# YTM32B1HA0 register map
Vendor: YTMicro; File version: 1.0
CPU: little endian, MPU, FPU, 2 interrupt priority bits
Registers are 32-bit, read-write, reset 0x0 unless marked. A register's access mark holds for its fields unless they carry their own. Offsets are from the block's base; [hi:lo] are bit positions; {n}, {i} and the like mark numbered series; 'fields as' and 'values as' point back to an identical list.

## SAI0
Base 0x401CC000; register names take the prefix SAI0_
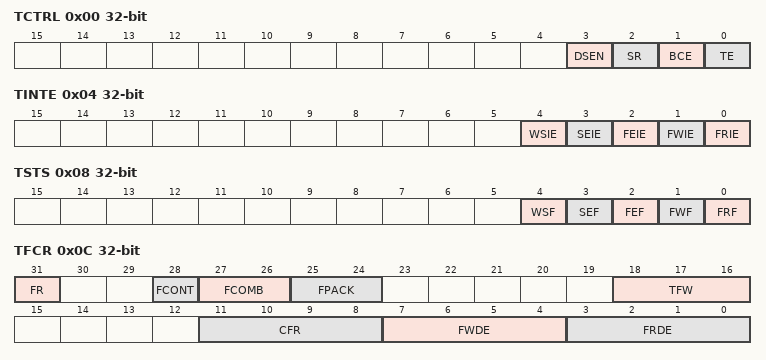
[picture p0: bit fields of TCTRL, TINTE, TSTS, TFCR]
0x00 TCTRL
  [3] DSEN — Configure the operation state of the transimitter in Deepsleep.
    0=Transmitter disable in Deepsleep; 1=Transmitter enable in Deepsleep
  [2] SR — When set, it will reset FIFO and the internal transmitter logic.
    0=No effect; 1=Software reset
  [1] BCE — Enables the transmit bit clock, separately from the TE.
    0=Transmit bit clock is disabled when TE is cleared; 1=Transmit bit clock is enabled
  [0] TE — Enable bit for the transmitter. After this bit is write 0, it remains set until the end of the current frame.
    0=Transmitter is disabled; 1=Transmitter is enabled
0x04 TINTE
  [all] fields
    0=Disable the interrupt; 1=Enable the interrupt
  [4] WSIE — Enable bit for word start interrupt.
  [3] SEIE — Enable bit for sync error interrupt.
  [2] FEIE — Enable bit for FIFO error interrupt.
  [1] FWIE — Enable bit for FIFO warning interrupt.
  [0] FRIE — Enable bit for FIFO request interrupt.
0x08 TSTS
  [4] WSF — Indicates the start of the word.
  [3] SEF — Indicates an error is detected on the frame sync which generated externally.
  [2] FEF — Indicates an FIFO underrun has been detected on enableb FIFOs.
  [1] FWF — Indicates at least one of the enabled FIFOs is empty.
  [0] FRF — Indicates at least one of the enabled FIFOs has words less or equal to the FIFO watermark.
0x0C TFCR
  [31] FR wo — FIFO software reset. Clears the data in the FIFO and sets the FIFO read pointer and write pointer to the same value. When the transmitter is disabled or the FIFO error occurs, this bit can be set.
  [28] FCONT — When configured, the SAI will continue transmitting when a FIFO error has been detected.
    0=After FIFO error occurs and the FIFO error flag is cleared, the SAI continues from the start of the next frame; 1=After FIFO error occurs and the FIFO error flag is cleared, the SAI continues from the same word that caused the FIFO error
  [27:26] FCOMB — When FIFO combine mode enabled on FIFO reads, the transmit data will alternate the read between the enabled FIFOs. The first word will be transmitted from the first enabled FIFO and the second word will be transmitted from the second FIFO. The first word of the frame is always transmitted from the first enabled FIFO. ewline When FIFO combine mode enabled on FIFO writes, soft writing to any FIFO data will alternate the write between the enabled FIFOs. The first write will store data in the first enabled FIFO and the second write will store data in the second enabled FIFO.
    0=FIFO combine mode disabled; 1=FIFO combine mode enabled on FIFO reads; 2=FIFO combine mode enabled on FIFO writes; 3=FIFO combine mode enabled on FIFO reads and FIFO writes
  [25:24] FPACK — Enalbes packing of 8-bit data or 16-bit data into 32-bit FIFO word. ewline The first word in each frame always start with a new 32-bit FIFO word.
    0=FIFO packing mode disabled; 1=8-bit FIFO packing mode enabled; 1=16-bit FIFO packing mode enabled
  [18:16] TFW — Configures the watermark level for the enabled FIFOs
  [11:8] CFR wo — Resets the FIFO pointers for the specific channel. It should only be set when a channel is disabled or the FIFO error flag is set.
  [7:4] FWDE — Enable the DMA request for the specific channel.
  [3:0] FRDE — Enable the DMA request for the specific channel.
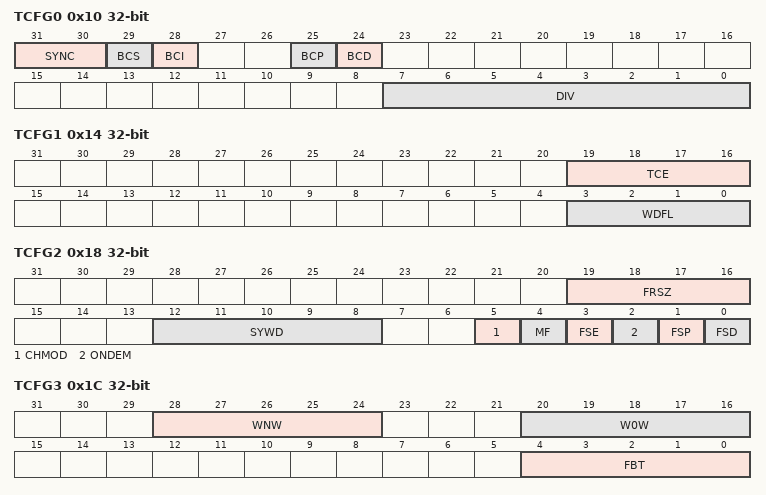
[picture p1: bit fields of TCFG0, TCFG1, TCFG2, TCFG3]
0x10 TCFG0
  [31:30] SYNC — Configures between asynchronous and synchronous modes of operation. In the synchronous mode, it operate with the synchronous bit clock and frame sync.
    0=Asynchronous mode; 1=Synchronous with the receiver(it should be in asynchronous mode); 2=Synchronous with another SAI transmitter(it should be in asynchronous mode); 3=Synchronous with another SAI receiver(it should be in asynchronous mode)
  [29] BCS — In asynchronous mode, swaps the bit clock with the receiver. This allows the transmitter and receiver to share the same bit clock, but the transmitter continues to use the transmit frame sync. ewline In synchronous mode, the transmitter and the receiver should be set to the same value. ewline When both set, the transmitter and the receiver both use the transmitter bit clock.
    0=Use the normal bit clock source; 1=Swap the bit clock source
  [28] BCI — When using an internally generated bit clock, enabling this bit will allow the transmitter to use the bit clock delayed by the pad. ewline When using an externally generated bit clock, it has no effect.
    0=No effect; 1=Use the bit clock delayed by the pad
  [25] BCP — Configures the polarity of the bit clock.
    0=Bit clock is active high with drive outputs on rising edge and sample inputs on falling edge; 1=Bit clock is active low with drive outputs on falling edge and sample inputs on rising edge
  [24] BCD — Configures the direction of the bit clock.
    0=Bit clock is generated externally in slave mode; 1=Bit clock is generated internally in master mode
  [7:0] DIV — Divide the audio master clock to generate teh bit clock. The division value is (DIV+1)*2
0x14 TCFG1
  [19:16] TCE — Enable the corresponding data channels for tranmit. Changing this field take effect immediately at the end of the frame.
  [3:0] WDFL
0x18 TCFG2
  [19:16] FRSZ — Configures the number of words in each frame. The number of words in the frame is (FRSZ+1).
  [12:8] SYWD — Configures the length of the frame sync in number of bit clock. The length is (SYWD+1) bit clock cycles.
  [5] CHMOD — Configures if the transmit data pins are TDM mode or ouput mode.
    0=TDM mode. The transmit data pins are tri-stated when slots are masked or channels are disabled.; 1=Output mode. The transmit data pins output zero when slots are masked or channels are disabled.
  [4] MF — Configures whether the LSB or the MSB is transmitted first.
    0=LSB first; 1=MSB first
  [3] FSE
    0=Frame sync asserts with the first bit of the frame; 1=Frame sync asserts one bit before the first bit of the frame
  [2] ONDEM — Configures that the frame sync is only generated when the FIFO warning flag is cleared and the frame sync is generated internally.
    0=Internal frame sync is generated continuously; 1=Internal frame sync is generated when the FIFO warning flag is clear
  [1] FSP — Configures the polarity of the frame sync.
    0=Frame sync is active high; 1=Frame sync is active low
  [0] FSD — Configures the direction of the frame sync.
    0=Frame sync is generated externally in slave mode; 1=Frame sync is generated internally in master mode
0x1C TCFG3
  [28:24] WNW — Configure the number of bits in each word except the first word in the frame. The number of bits in each word is (WNW+1) and should be no less than 8.
  [20:16] W0W — Configure the number of bits in the first word in each frame. The number of bits in the first word is (W0W+1) and should be no less than 8.
  [4:0] FBT — Configures the bit index for the first bit transmitted for each word.
{0x20+4i} TDATA{i} (i=0..3)
  [31:0] TDATA wo — Writes to this field will push the data into the FIFO when the FIFO is not full.
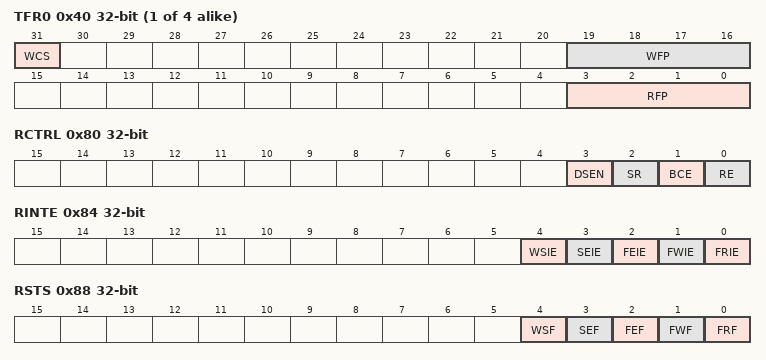
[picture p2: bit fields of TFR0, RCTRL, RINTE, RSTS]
{0x40+4i} TFR{i} (i=0..3)
  [31] WCS ro — Indicates FIFO of this channel is to be write next during FIFO combine mode.
  [19:16] WFP
  [3:0] RFP
0x60 TMR
  [15:0] TWM — Configure whether the transmit word is masked for the corresponding word in the frame.
0x80 RCTRL
  [3] DSEN — Configure the operation state of the receiver in Deepsleep.
    0=Receiver disable in Deepsleep; 1=Receiver enable in Deepsleep
  [2] SR — When set, it will reset FIFO and the internal receiver logic.
    0=No effect; 1=Software reset
  [1] BCE — Enables the receive bit clock, separately from the RE.
    0=Receive bit clock is disabled when RE is cleared; 1=Receive bit clock is enabled
  [0] RE — Enable bit for the receiver. After this bit is write 0, it remains set until the end of the current frame.
    0=Receiver is disabled; 1=Receiver is enabled
0x84 RINTE
  fields as TINTE
0x88 RSTS
  [4] WSF — Indicates the start of the word.
  [3] SEF — Indicates an error is detected on the frame sync which generated externally.
  [2] FEF — Indicates an FIFO overrun has been detected on enableb FIFOs.
  [1] FWF — Indicates at least one of the enabled FIFOs is full.
  [0] FRF — Indicates at least one of the enabled FIFOs has words greater or than the FIFO watermark.
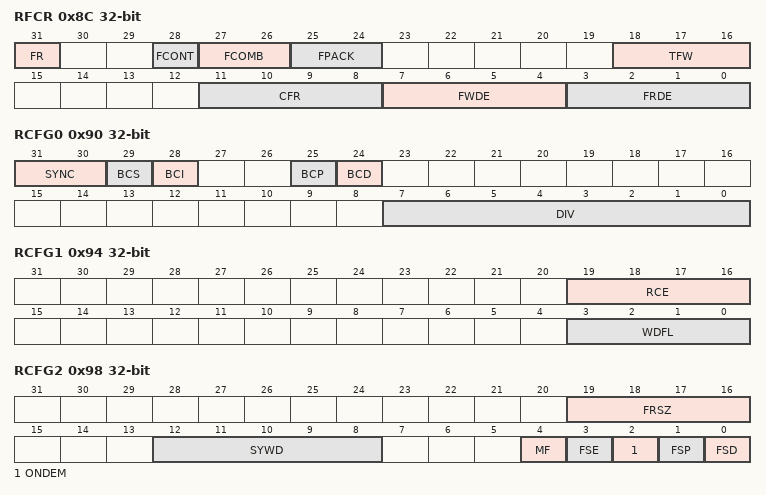
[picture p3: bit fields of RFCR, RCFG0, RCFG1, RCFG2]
0x8C RFCR
  [31] FR wo — FIFO software reset. Clears the data in the FIFO and sets the FIFO read pointer and write pointer to the same value. When the receiver is disabled or the FIFO error occurs, this bit can be set.
  [28] FCONT — When configured, the SAI will continue transmitting when a FIFO error has been detected.
    values as TFCR.FCONT
  [27:26] FCOMB — When FIFO combine mode enabled on FIFO write, the receive data will alternate the write between the enabled FIFOs. The first word will be stored to the first enabled FIFO and the second word will be stored to the second FIFO. The first word of the frame is always stored to the first enabled FIFO. ewline When FIFO combine mode enabled on FIFO reads, soft reading to any FIFO data will alternate the read between the enabled FIFOs. The first read will get data from the first enabled FIFO and the second read will get data from the second enabled FIFO.
    0=FIFO combine mode disabled; 1=FIFO combine mode enabled on FIFO writes; 2=FIFO combine mode enabled on FIFO reads; 3=FIFO combine mode enabled on FIFO reads and FIFO writes
  [25:24] FPACK — Enalbes packing of 8-bit data or 16-bit data into 32-bit FIFO word. ewline The first word in each frame always start with a new 32-bit FIFO word.
    values as TFCR.FPACK
  [18:16] TFW — Configures the watermark level for the enabled FIFOs
  [11:8] CFR wo — Resets the FIFO pointers for the specific channel. It should only be set when a channel is disabled or the FIFO error flag is set.
  [7:4] FWDE — Enable the DMA request for the specific channel.
  [3:0] FRDE — Enable the DMA request for the specific channel.
0x90 RCFG0
  [31:30] SYNC — Configures between asynchronous and synchronous modes of operation. In the synchronous mode, it operate with the synchronous bit clock and frame sync.
    0=Asynchronous mode; 1=Synchronous with the transmitter(it should be in asynchronous mode); 2=Synchronous with another SAI receiver(it should be in asynchronous mode); 3=Synchronous with another SAI transmitter(it should be in asynchronous mode)
  [29] BCS — In asynchronous mode, swaps the bit clock with the transmitter. his allows the transmitter and receiver to share the same bit clock, but the receiver continues to use the receive frame sync. ewline In synchronous mode, the transmitter and the receiver should be set to the same value. ewline When both set, the transmitter and the receiver both use the receiver bit clock.
    values as TCFG0.BCS
  [28] BCI — When using an internally generated bit clock, enabling this bit will allow the receiver to use the bit clock delayed by the pad. ewline When using an externally generated bit clock, it has no effect.
    0=No effect; 1=Use the bit clock delayed by the pad
  [25] BCP — Configures the polarity of the bit clock.
    values as TCFG0.BCP
  [24] BCD — Configures the direction of the bit clock.
    values as TCFG0.BCD
  [7:0] DIV — Divide the audio master clock to generate teh bit clock. The division value is (DIV+1)*2
0x94 RCFG1
  [19:16] RCE — Enable the corresponding data channels for receive. Changing this field take effect immediately at the end of the frame.
  [3:0] WDFL
0x98 RCFG2
  [19:16] FRSZ — Configures the number of words in each frame. The number of words in the frame is (FRSZ+1).
  [12:8] SYWD — Configures the length of the frame sync in number of bit clock. The length is (SYWD+1) bit clock cycles.
  [4] MF — Configures whether the LSB or the MSB is received first.
    0=LSB first; 1=MSB first
  [3] FSE
    values as TCFG2.FSE
  [2] ONDEM — Configures that the frame sync is only generated when the FIFO warning flag is cleared and the frame sync is generated internally.
    values as TCFG2.ONDEM
  [1] FSP — Configures the polarity of the frame sync.
    0=Frame sync is active high; 1=Frame sync is active low
  [0] FSD — Configures the direction of the frame sync.
    values as TCFG2.FSD
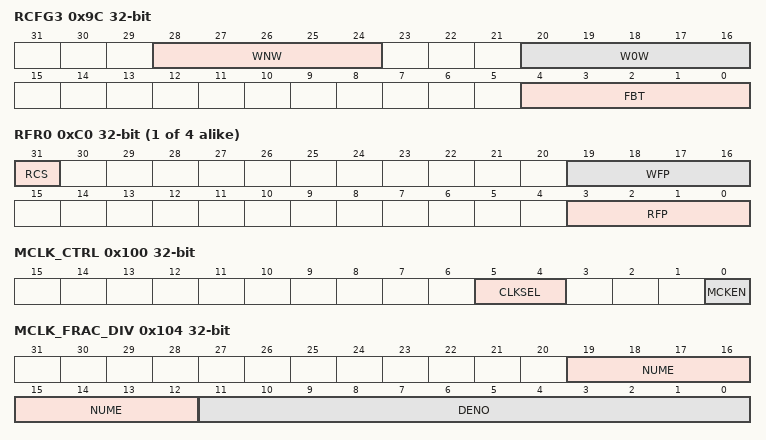
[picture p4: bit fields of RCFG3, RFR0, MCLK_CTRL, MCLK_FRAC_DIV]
0x9C RCFG3
  [28:24] WNW — Configure the number of bits in each word except the first word in the frame. The number of bits in each word is (WNW+1) and should be no less than 8.
  [20:16] W0W — Configure the number of bits in the first word in each frame. The number of bits in the first word is (W0W+1) and should be no less than 8.
  [4:0] FBT — Configures the bit index for the first bit received for each word.
{0xA0+4i} RDATA{i} (i=0..3)
  [31:0] RDATA ro — Read this field will return the data from the FIFO when the FIFO is not empty.
{0xC0+4i} RFR{i} (i=0..3)
  [31] RCS ro — Indicates FIFO of this channel is to be read next during FIFO combine mode.
  [19:16] WFP
  [3:0] RFP
0xE0 RMR
  [15:0] RWM — Configure whether the receive word is masked for the corresponding word in the frame.
0x100 MCLK_CTRL
  [5:4] CLKSEL — Cofigures the source of MCLK.
    0=Bus Clock selected; 1=Master Clock 1 selected; 2=Master Clock 2 selected; 3=Master Clock 3 selected
  [0] MCKEN — Enable the MCLK.
0x104 MCLK_FRAC_DIV
  [19:12] NUME — Indicate the numerator part of the fractional divider. The numerator is (NUME+1).
  [11:0] DENO — Indicate the denominator part of the fractional divider. The denominator is (DENO+1).

## SAI1
Base 0x401D0000; register names take the prefix SAI1_
Registers as SAI0.
